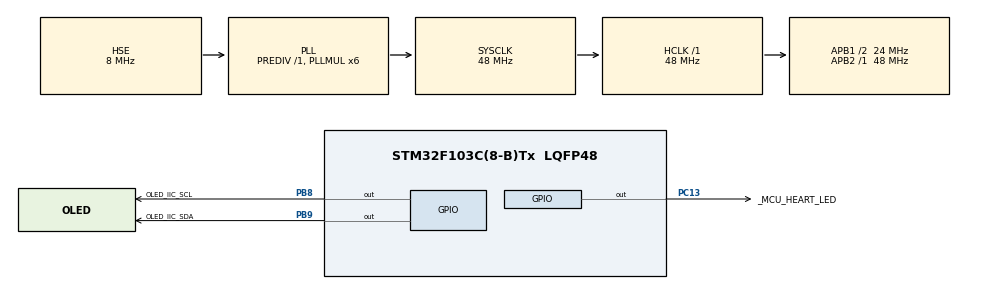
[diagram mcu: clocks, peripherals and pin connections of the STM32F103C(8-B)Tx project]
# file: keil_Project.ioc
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Mcu.Family=STM32F1
Mcu.Name=STM32F103C(8-B)Tx
Mcu.Package=LQFP48
NVIC.PriorityGroup=NVIC_PRIORITYGROUP_4
NVIC.TIM1_UP_IRQn=true\:15\:0\:false\:false\:true\:false\:true\:true
NVIC.TIM4_IRQn=true\:4\:0\:true\:false\:true\:true\:true\:true
NVIC.TimeBase=TIM1_UP_IRQn
NVIC.TimeBaseIP=TIM1
PA13.Mode=Serial_Wire
PA13.Signal=SYS_JTMS-SWDIO
PA14.Mode=Serial_Wire
PA14.Signal=SYS_JTCK-SWCLK
PB8.GPIO_Label=OLED_IIC_SCL
PB8.GPIO_ModeDefaultOutputPP=GPIO_MODE_OUTPUT_PP
PB8.GPIO_PuPd=GPIO_PULLUP
PB8.GPIO_Speed=GPIO_SPEED_FREQ_HIGH
PB8.PinState=GPIO_PIN_SET
PB8.Signal=GPIO_Output
PB9.GPIO_Label=OLED_IIC_SDA
PB9.GPIO_ModeDefaultOutputPP=GPIO_MODE_OUTPUT_PP
PB9.GPIO_PuPd=GPIO_PULLUP
PB9.GPIO_Speed=GPIO_SPEED_FREQ_HIGH
PB9.PinState=GPIO_PIN_SET
PB9.Signal=GPIO_Output
PC13-TAMPER-RTC.GPIO_Label=_MCU_HEART_LED
PC13-TAMPER-RTC.GPIO_ModeDefaultOutputPP=GPIO_MODE_OUTPUT_PP
PC13-TAMPER-RTC.GPIO_PuPd=GPIO_PULLUP
PC13-TAMPER-RTC.GPIO_Speed=GPIO_SPEED_FREQ_LOW
PC13-TAMPER-RTC.PinState=GPIO_PIN_SET
PC13-TAMPER-RTC.Signal=GPIO_Output
PC14-OSC32_IN.Mode=LSE-External-Oscillator
PC14-OSC32_IN.Signal=RCC_OSC32_IN
PC15-OSC32_OUT.Mode=LSE-External-Oscillator
PC15-OSC32_OUT.Signal=RCC_OSC32_OUT
PD0-OSC_IN.Mode=HSE-External-Oscillator
PD0-OSC_IN.Signal=RCC_OSC_IN
PD1-OSC_OUT.Mode=HSE-External-Oscillator
PD1-OSC_OUT.Signal=RCC_OSC_OUT
ProjectManager.HeapSize=0x200
ProjectManager.StackSize=0x400
ProjectManager.TargetToolchain=MDK-ARM V5.32
RCC.AHBFreq_Value=48000000
RCC.APB1CLKDivider=RCC_HCLK_DIV2
RCC.APB1Freq_Value=24000000
RCC.APB1TimFreq_Value=48000000
RCC.APB2Freq_Value=48000000
RCC.APB2TimFreq_Value=48000000
RCC.HCLKFreq_Value=48000000
RCC.PLLMUL=RCC_PLL_MUL6
RCC.PLLSourceVirtual=RCC_PLLSOURCE_HSE
RCC.SYSCLKFreq_VALUE=48000000
RCC.SYSCLKSource=RCC_SYSCLKSOURCE_PLLCLK
RCC.USBFreq_Value=48000000
TIM4.AutoReloadPreload=TIM_AUTORELOAD_PRELOAD_ENABLE
TIM4.Period=9999
TIM4.Prescaler=23
TIM4.TIM_MasterSlaveMode=TIM_MASTERSLAVEMODE_DISABLE
VP_SYS_VS_tim1.Mode=TIM1
VP_TIM4_VS_ClockSourceITR.Mode=TriggerSource_ITR0
board=custom

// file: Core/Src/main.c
/* USER CODE BEGIN Header */
/**
  ******************************************************************************
  * @file           : main.c
  * @brief          : Main program body
  ******************************************************************************
  * @attention
  *
  * Copyright (c) 2022 STMicroelectronics.
  * All rights reserved.
  *
  * This software is licensed under terms that can be found in the LICENSE file
  * in the root directory of this software component.
  * If no LICENSE file comes with this software, it is provided AS-IS.
  *
  ******************************************************************************
  */
/* USER CODE END Header */
#include "main.h"

/* USER CODE BEGIN Includes */
#include "api_misc.h"
#include "app_process.h"
#include "oled_0_96_driver.h"
/* USER CODE END Includes */

TIM_HandleTypeDef htim4;

void SystemClock_Config(void);
static void MX_GPIO_Init(void);
static void MX_TIM4_Init(void);

int main(void)
{
  /* USER CODE BEGIN 1 */
	uint8_t t;
  /* USER CODE END 1 */

  /* MCU Configuration--------------------------------------------------------*/

  /* Reset of all peripherals, Initializes the Flash interface and the Systick. */
  HAL_Init();

  /* Configure the system clock */
  SystemClock_Config();

  /* Initialize all configured peripherals */
  MX_GPIO_Init();
  MX_TIM4_Init();
  /* USER CODE BEGIN 2 */
	OLED_Init();
	OLED_Clear();
	t=' ';
		OLED_ShowCHinese(0,0,0);//��
				OLED_ShowCHinese(18,0,1);//��
		OLED_ShowCHinese(36,0,2);//԰
		OLED_ShowCHinese(54,0,3);//��
		OLED_ShowCHinese(72,0,4);//��
		OLED_ShowCHinese(90,0,5);//��
		OLED_ShowCHinese(108,0,6);//��
  /* USER CODE END 2 */

  /* Infinite loop */
  while (1)
  {

    /* USER CODE BEGIN 3 */
		_mcu_heart_process();
  }
  /* USER CODE END 3 */
}

void SystemClock_Config(void)
{
  RCC_OscInitTypeDef RCC_OscInitStruct = {0};
  RCC_ClkInitTypeDef RCC_ClkInitStruct = {0};

  /** Initializes the RCC Oscillators according to the specified parameters
  * in the RCC_OscInitTypeDef structure.
  */
  RCC_OscInitStruct.OscillatorType = RCC_OSCILLATORTYPE_HSE;
  RCC_OscInitStruct.HSEState = RCC_HSE_ON;
  RCC_OscInitStruct.HSEPredivValue = RCC_HSE_PREDIV_DIV1;
  RCC_OscInitStruct.HSIState = RCC_HSI_ON;
  RCC_OscInitStruct.PLL.PLLState = RCC_PLL_ON;
  RCC_OscInitStruct.PLL.PLLSource = RCC_PLLSOURCE_HSE;
  RCC_OscInitStruct.PLL.PLLMUL = RCC_PLL_MUL6;
  if (HAL_RCC_OscConfig(&RCC_OscInitStruct) != HAL_OK)
  {
    Error_Handler();
  }

  /** Initializes the CPU, AHB and APB buses clocks
  */
  RCC_ClkInitStruct.ClockType = RCC_CLOCKTYPE_HCLK|RCC_CLOCKTYPE_SYSCLK
                              |RCC_CLOCKTYPE_PCLK1|RCC_CLOCKTYPE_PCLK2;
  RCC_ClkInitStruct.SYSCLKSource = RCC_SYSCLKSOURCE_PLLCLK;
  RCC_ClkInitStruct.AHBCLKDivider = RCC_SYSCLK_DIV1;
  RCC_ClkInitStruct.APB1CLKDivider = RCC_HCLK_DIV2;
  RCC_ClkInitStruct.APB2CLKDivider = RCC_HCLK_DIV1;

  if (HAL_RCC_ClockConfig(&RCC_ClkInitStruct, FLASH_LATENCY_1) != HAL_OK)
  {
    Error_Handler();
  }
}

static void MX_TIM4_Init(void)
{

  TIM_SlaveConfigTypeDef sSlaveConfig = {0};
  TIM_MasterConfigTypeDef sMasterConfig = {0};

  htim4.Instance = TIM4;
  htim4.Init.Prescaler = 23;
  htim4.Init.CounterMode = TIM_COUNTERMODE_UP;
  htim4.Init.Period = 9999;
  htim4.Init.ClockDivision = TIM_CLOCKDIVISION_DIV1;
  htim4.Init.AutoReloadPreload = TIM_AUTORELOAD_PRELOAD_ENABLE;
  if (HAL_TIM_Base_Init(&htim4) != HAL_OK)
  {
    Error_Handler();
  }
  sSlaveConfig.SlaveMode = TIM_SLAVEMODE_DISABLE;
  sSlaveConfig.InputTrigger = TIM_TS_ITR0;
  if (HAL_TIM_SlaveConfigSynchro(&htim4, &sSlaveConfig) != HAL_OK)
  {
    Error_Handler();
  }
  sMasterConfig.MasterOutputTrigger = TIM_TRGO_RESET;
  sMasterConfig.MasterSlaveMode = TIM_MASTERSLAVEMODE_DISABLE;
  if (HAL_TIMEx_MasterConfigSynchronization(&htim4, &sMasterConfig) != HAL_OK)
  {
    Error_Handler();
  }
  /* USER CODE BEGIN TIM4_Init 2 */
	HAL_TIM_Base_Start_IT(&htim4);
  /* USER CODE END TIM4_Init 2 */

}

static void MX_GPIO_Init(void)
{
  GPIO_InitTypeDef GPIO_InitStruct = {0};

  /* GPIO Ports Clock Enable */
  __HAL_RCC_GPIOC_CLK_ENABLE();
  __HAL_RCC_GPIOD_CLK_ENABLE();
  __HAL_RCC_GPIOA_CLK_ENABLE();
  __HAL_RCC_GPIOB_CLK_ENABLE();

  /*Configure GPIO pin Output Level */
  HAL_GPIO_WritePin(_MCU_HEART_LED_GPIO_Port, _MCU_HEART_LED_Pin, GPIO_PIN_SET);

  /*Configure GPIO pin Output Level */
  HAL_GPIO_WritePin(GPIOB, OLED_IIC_SCL_Pin|OLED_IIC_SDA_Pin, GPIO_PIN_SET);

  /*Configure GPIO pin : _MCU_HEART_LED_Pin */
  GPIO_InitStruct.Pin = _MCU_HEART_LED_Pin;
  GPIO_InitStruct.Mode = GPIO_MODE_OUTPUT_PP;
  GPIO_InitStruct.Pull = GPIO_PULLUP;
  GPIO_InitStruct.Speed = GPIO_SPEED_FREQ_LOW;
  HAL_GPIO_Init(_MCU_HEART_LED_GPIO_Port, &GPIO_InitStruct);

  /*Configure GPIO pins : OLED_IIC_SCL_Pin OLED_IIC_SDA_Pin */
  GPIO_InitStruct.Pin = OLED_IIC_SCL_Pin|OLED_IIC_SDA_Pin;
  GPIO_InitStruct.Mode = GPIO_MODE_OUTPUT_PP;
  GPIO_InitStruct.Pull = GPIO_PULLUP;
  GPIO_InitStruct.Speed = GPIO_SPEED_FREQ_HIGH;
  HAL_GPIO_Init(GPIOB, &GPIO_InitStruct);

}

void HAL_TIM_PeriodElapsedCallback(TIM_HandleTypeDef *htim)
{
  if (htim->Instance == TIM1) {
    HAL_IncTick();
  }
  /* USER CODE BEGIN Callback 1 */
	else if(htim->Instance == TIM4)
	{
		TIMER_EXECUTE(g_led_heart_timer_cnt);
	}
  /* USER CODE END Callback 1 */
}

void Error_Handler(void)
{
  __disable_irq();
  while (1)
  {
  }
}
